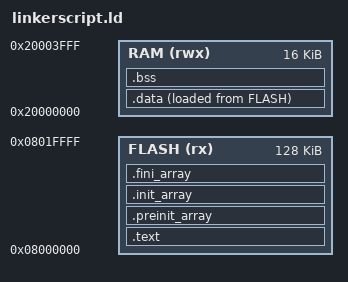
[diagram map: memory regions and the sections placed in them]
MEMORY
{
    FLASH (rx)  : ORIGIN = 0x08000000, LENGTH = 128K
    RAM   (rwx) : ORIGIN = 0x20000000, LENGTH = 16K
}

_estack = ORIGIN(RAM) + LENGTH(RAM);
_stack = _estack;

SECTIONS
{
    .text :
    {
        KEEP(*(.vectors))
        *(.text*)
        *(.rodata*)
        . = ALIGN(4);
    } > FLASH

    .preinit_array :
    {
        . = ALIGN(4);
        __preinit_array_start = .;
        KEEP(*(.preinit_array))
        __preinit_array_end = .;
    } > FLASH

    .init_array :
    {
        . = ALIGN(4);
        __init_array_start = .;
        KEEP(*(.init_array))
        __init_array_end = .;
    } > FLASH

    .fini_array :
    {
        . = ALIGN(4);
        __fini_array_start = .;
        KEEP(*(.fini_array))
        __fini_array_end = .;
    } > FLASH

    .data :
    {
        . = ALIGN(4);
        _data = .;
        *(.data*)
        . = ALIGN(4);
        _edata = .;
    } > RAM AT > FLASH

    _data_loadaddr = LOADADDR(.data);

    .bss :
    {
        . = ALIGN(4);
        *(.bss*)
        *(COMMON)
        . = ALIGN(4);
        _ebss = .;
    } > RAM
}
